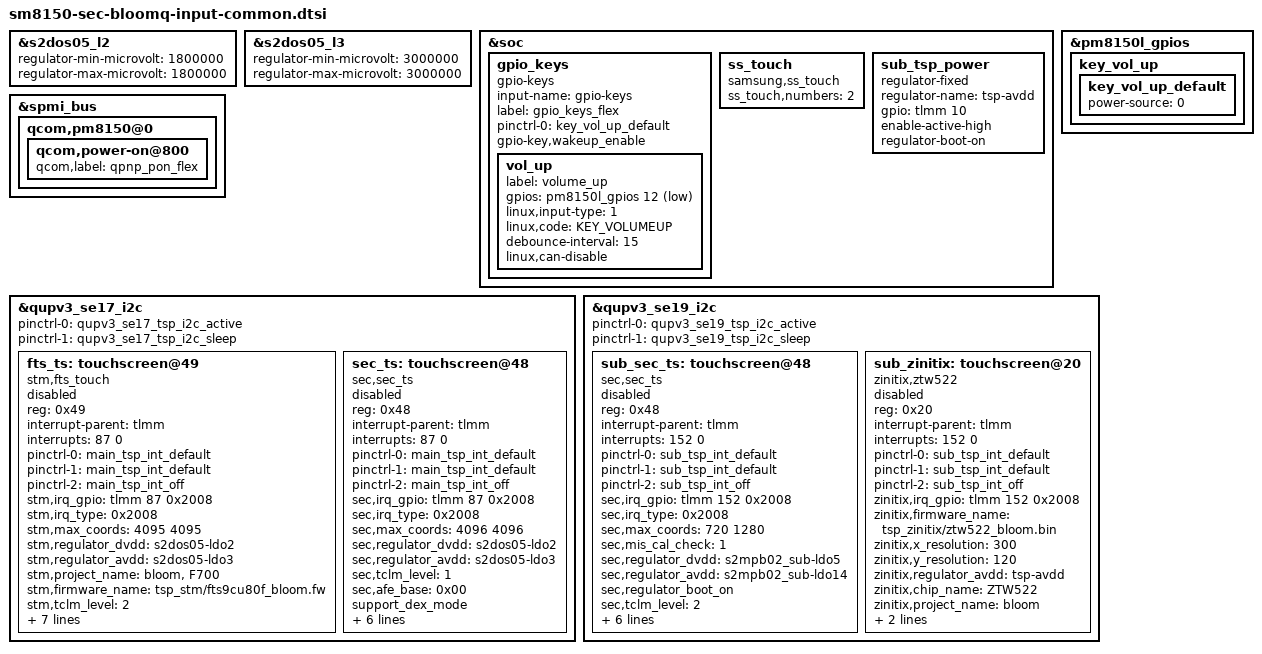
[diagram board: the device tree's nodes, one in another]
/* Copyright (c) 2016-2017, The Linux Foundation. All rights reserved.
 *
 * This program is free software; you can redistribute it and/or modify
 * it under the terms of the GNU General Public License version 2 and
 * only version 2 as published by the Free Software Foundation.
 *
 * This program is distributed in the hope that it will be useful,
 * but WITHOUT ANY WARRANTY; without even the implied warranty of
 * MERCHANTABILITY or FITNESS FOR A PARTICULAR PURPOSE.  See the
 * GNU General Public License for more details.
 */

#include <dt-bindings/input/input.h>

&s2dos05_l2 {	/* tsp_io */
	regulator-min-microvolt = <1800000>;
	regulator-max-microvolt = <1800000>;
//	regulator-boot-on;
};

&s2dos05_l3 {	/* tsp_avdd */
	regulator-min-microvolt = <3000000>;
	regulator-max-microvolt = <3000000>;
//	regulator-boot-on;
};

/delete-node/ &gpio_keys;
&soc {
	gpio_keys: gpio_keys {
		status = "ok";
		compatible = "gpio-keys";
		input-name = "gpio-keys";
		label = "gpio_keys_flex";
		pinctrl-names = "default";
		pinctrl-0 = <&key_vol_up_default>;
		gpio-key,wakeup_enable;

		vol_up {
			label = "volume_up";
			gpios = <&pm8150l_gpios 12 GPIO_ACTIVE_LOW>;
			linux,input-type = <1>;
			linux,code = <KEY_VOLUMEUP>;
			debounce-interval = <15>;
			linux,can-disable;
		};
	};

	ss_touch {
		compatible = "samsung,ss_touch";
		ss_touch,numbers = <2>;
	};

	sub_tsp_power {
		compatible = "regulator-fixed";
		status = "okay";
		regulator-name = "tsp-avdd";
		gpio = <&tlmm 10 0>;
		enable-active-high;
		regulator-boot-on;
	};
};

&pm8150l_gpios {
	key_vol_up {
		key_vol_up_default: key_vol_up_default {
			power-source = <0>;
		};
	};
};

&spmi_bus {
	qcom,pm8150@0 {
		qcom,power-on@800 {
			qcom,label = "qpnp_pon_flex";
		};
	};
};

&qupv3_se17_i2c { /* i2c@0xc80000, gpio55/56 */
	pinctrl-0 = <&qupv3_se17_tsp_i2c_active>;
	pinctrl-1 = <&qupv3_se17_tsp_i2c_sleep>;
	status = "ok";

	/* stm */
	fts_ts: touchscreen@49 {
		status = "disabled";
		compatible = "stm,fts_touch";
		reg = <0x49>;
		interrupt-parent = <&tlmm>;
		interrupts = <87 0>;
		pinctrl-names = "default", "on_state", "off_state";
		pinctrl-0 = <&main_tsp_int_default>;
		pinctrl-1 = <&main_tsp_int_default>;
		pinctrl-2 = <&main_tsp_int_off>;
		stm,irq_gpio = <&tlmm 87 0x2008>;
		stm,irq_type = <0x2008>;
		stm,max_coords = <4095 4095>;	/* x y */
		stm,regulator_dvdd = "s2dos05-ldo2";
		stm,regulator_avdd = "s2dos05-ldo3";
		stm,project_name = "bloom", "F700";
		stm,firmware_name = "tsp_stm/fts9cu80f_bloom.fw";
		stm,tclm_level = <2>;
		stm,afe_base = <0x000B>;
		stm,enable_settings_aot;
		support_dex_mode;
		support_ear_detect;
		stm,ss_touch_num = <1>;
/*		sync-reportrate-120 = "Y";*/
		support_open_short_test;
		support_mis_calibration_test;
	};
	
	sec_ts: touchscreen@48 {
		status = "disabled";
		compatible = "sec,sec_ts";
		reg = <0x48>;
		interrupt-parent = <&tlmm>;
		interrupts = <87 0>;
		pinctrl-names = "default", "on_state", "off_state";
		pinctrl-0 = <&main_tsp_int_default>;
		pinctrl-1 = <&main_tsp_int_default>;
		pinctrl-2 = <&main_tsp_int_off>;
		sec,irq_gpio = <&tlmm 87 0x2008>;
		sec,irq_type = <0x2008>;
		sec,max_coords = <4096 4096>; /* x y */
		sec,regulator_dvdd = "s2dos05-ldo2";
		sec,regulator_avdd = "s2dos05-ldo3";
//		sec,regulator_boot_on;
		sec,tclm_level = <1>;
		sec,afe_base = <0x00>;
		support_dex_mode;
		sec,i2c-burstmax = <0x8>;
		sec,ss_touch_num = <1>;
		enable_settings_aot;
		sec,area-size = <132 266 341>;
		support_ear_detect_mode;
		sync-reportrate-120 = "Y";
	};

};

&qupv3_se19_i2c { /* i2c@0xc88000, gpio57/58 */
	pinctrl-0 = <&qupv3_se19_tsp_i2c_active>;
	pinctrl-1 = <&qupv3_se19_tsp_i2c_sleep>;
	status = "ok";

	sub_sec_ts: touchscreen@48 {
		status = "disabled";
		compatible = "sec,sec_ts";
		reg = <0x48>;
		interrupt-parent = <&tlmm>;
		interrupts = <152 0>;
		pinctrl-names = "default", "on_state", "off_state";
		pinctrl-0 = <&sub_tsp_int_default>;
		pinctrl-1 = <&sub_tsp_int_default>;
		pinctrl-2 = <&sub_tsp_int_off>;
/*		sec,icid_match_value = <1>;*/
/*		sec,tsp-id_gpio = <&pm8005_gpios 1 0>;*/
		sec,irq_gpio = <&tlmm 152 0x2008>;
		sec,irq_type = <0x2008>;
		sec,max_coords = <720 1280>; /* x y */
		sec,mis_cal_check = <1>;
		sec,regulator_dvdd = "s2mpb02_sub-ldo5";
		sec,regulator_avdd = "s2mpb02_sub-ldo14";
		sec,regulator_boot_on;
/*		sec,always_lpmode = <1>;*/
		sec,tclm_level = <2>;
		sec,afe_base = <0x0208>;
		sec,firmware_name = "tsp_sec/y761_winner.bin";
		sec,i2c-burstmax = <0x01000000>;
		sec,factory_item_version = <2>;
		sec,ss_touch_num = <2>;
		support_dex_mode;
	};

	/* ZTW522 */
	sub_zinitix: touchscreen@20 {
		status = "disabled";
		compatible = "zinitix,ztw522";
		reg = <0x20>;
		interrupt-parent = <&tlmm>;
		interrupts = <152 0>;
		pinctrl-names = "default", "on_state", "off_state";
		pinctrl-0 = <&sub_tsp_int_default>;
		pinctrl-1 = <&sub_tsp_int_default>;
		pinctrl-2 = <&sub_tsp_int_off>;
		zinitix,irq_gpio = <&tlmm 152 0x2008>;
		zinitix,firmware_name = "tsp_zinitix/ztw522_bloom.bin";
		zinitix,x_resolution = <300>;
		zinitix,y_resolution = <120>;
		zinitix,regulator_avdd = "tsp-avdd";
		zinitix,chip_name = "ZTW522";
		zinitix,project_name = "bloom";
		zinitix,page_size = <128>;
		zinitix,aot;
/*
		zinitix,spay;
		zinitix,aod;
		zinitix,tclm_level = <0x02>;
		zinitix,afe_base = <0x910B>;
		zinitix,mis_cal_check;
		zinitix,factory_item_version = <6>;
		support_ear_detect_mode;
*/
	};
};

